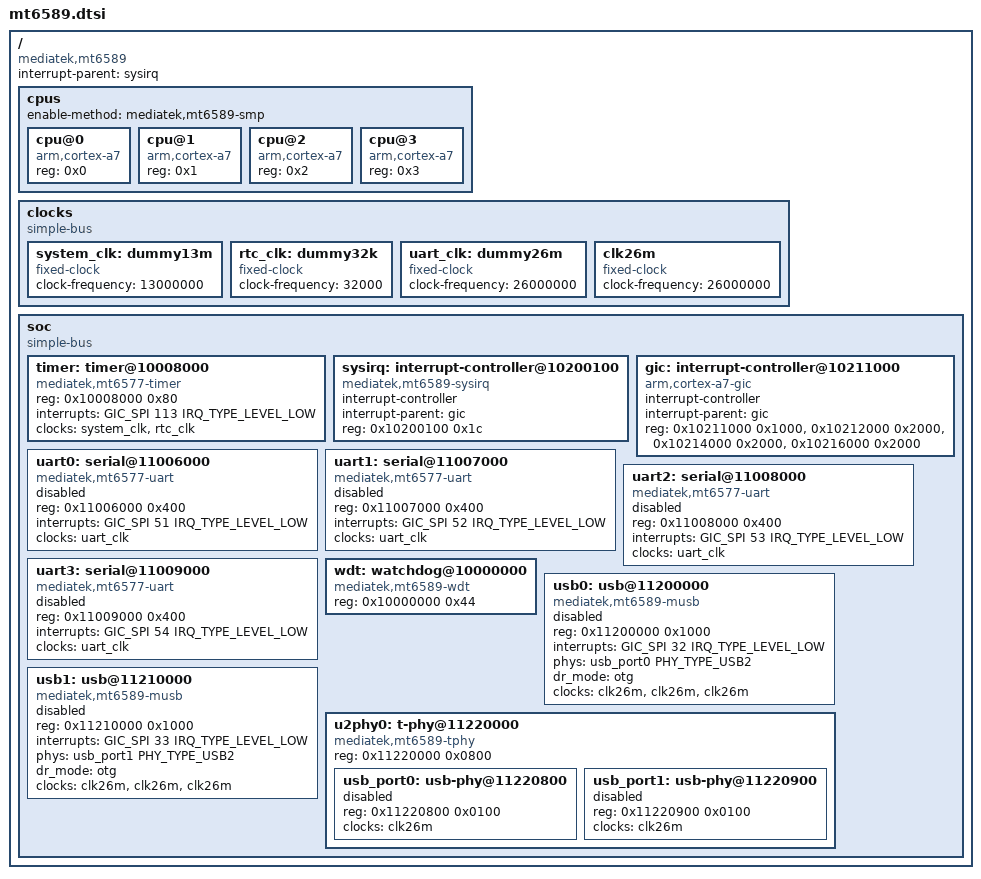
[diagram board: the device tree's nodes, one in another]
// SPDX-License-Identifier: GPL-2.0+
/*
 * Copyright (c) 2014 MundoReader S.L.
 * Author: Matthias Brugger <matthias.bgg@gmail.com>
 *
*/

#include <dt-bindings/interrupt-controller/irq.h>
#include <dt-bindings/interrupt-controller/arm-gic.h>
#include <dt-bindings/phy/phy.h>

/ {
	#address-cells = <1>;
	#size-cells = <1>;
	compatible = "mediatek,mt6589";
	interrupt-parent = <&sysirq>;

	cpus: cpus {
		#address-cells = <1>;
		#size-cells = <0>;
		enable-method = "mediatek,mt6589-smp";

		cpu@0 {
			device_type = "cpu";
			compatible = "arm,cortex-a7";
			reg = <0x0>;
		};
		cpu@1 {
			device_type = "cpu";
			compatible = "arm,cortex-a7";
			reg = <0x1>;
		};
		cpu@2 {
			device_type = "cpu";
			compatible = "arm,cortex-a7";
			reg = <0x2>;
		};
		cpu@3 {
			device_type = "cpu";
			compatible = "arm,cortex-a7";
			reg = <0x3>;
		};

	};

	clocks {
		#address-cells = <1>;
		#size-cells = <1>;
		compatible = "simple-bus";
		ranges;

		system_clk: dummy13m {
			compatible = "fixed-clock";
			clock-frequency = <13000000>;
			#clock-cells = <0>;
		};

		rtc_clk: dummy32k {
			compatible = "fixed-clock";
			clock-frequency = <32000>;
			#clock-cells = <0>;
		};

		uart_clk: dummy26m {
			compatible = "fixed-clock";
			clock-frequency = <26000000>;
			#clock-cells = <0>;
		};

		clk26m: clk26m {
			compatible = "fixed-clock";
			clock-frequency = <26000000>;
			#clock-cells = <0>;
		};
	};

	soc {
		#address-cells = <1>;
		#size-cells = <1>;
		compatible = "simple-bus";
		ranges;

		timer: timer@10008000 {
			compatible = "mediatek,mt6577-timer";
			reg = <0x10008000 0x80>;
			interrupts = <GIC_SPI 113 IRQ_TYPE_LEVEL_LOW>;
			clocks = <&system_clk>, <&rtc_clk>;
			clock-names = "system-clk", "rtc-clk";
		};

		sysirq: interrupt-controller@10200100 {
			compatible = "mediatek,mt6589-sysirq",
				     "mediatek,mt6577-sysirq";
			interrupt-controller;
			#interrupt-cells = <3>;
			interrupt-parent = <&gic>;
			reg = <0x10200100 0x1c>;
		};

		gic: interrupt-controller@10211000 {
			compatible = "arm,cortex-a7-gic";
			interrupt-controller;
			#interrupt-cells = <3>;
			interrupt-parent = <&gic>;
			reg = <0x10211000 0x1000>,
			      <0x10212000 0x2000>,
			      <0x10214000 0x2000>,
			      <0x10216000 0x2000>;
		};

		uart0: serial@11006000 {
			compatible = "mediatek,mt6577-uart";
			reg = <0x11006000 0x400>;
			interrupts = <GIC_SPI 51 IRQ_TYPE_LEVEL_LOW>;
			clocks = <&uart_clk>;
			status = "disabled";
		};

		uart1: serial@11007000 {
			compatible = "mediatek,mt6577-uart";
			reg = <0x11007000 0x400>;
			interrupts = <GIC_SPI 52 IRQ_TYPE_LEVEL_LOW>;
			clocks = <&uart_clk>;
			status = "disabled";
		};

		uart2: serial@11008000 {
			compatible = "mediatek,mt6577-uart";
			reg = <0x11008000 0x400>;
			interrupts = <GIC_SPI 53 IRQ_TYPE_LEVEL_LOW>;
			clocks = <&uart_clk>;
			status = "disabled";
		};

		uart3: serial@11009000 {
			compatible = "mediatek,mt6577-uart";
			reg = <0x11009000 0x400>;
			interrupts = <GIC_SPI 54 IRQ_TYPE_LEVEL_LOW>;
			clocks = <&uart_clk>;
			status = "disabled";
		};

		wdt: watchdog@10000000 {
			compatible = "mediatek,mt6589-wdt";
			reg = <0x10000000 0x44>;
		};

		/* USB 2.0 */
		usb0: usb@11200000 {
			compatible = "mediatek,mt6589-musb",
				     "mediatek,mtk-musb";
			reg = <0x11200000 0x1000>;
			interrupts = <GIC_SPI 32 IRQ_TYPE_LEVEL_LOW>;
			interrupt-names = "mc";
			phys = <&usb_port0 PHY_TYPE_USB2>;
			dr_mode = "otg";
			clocks = <&clk26m>, <&clk26m>, <&clk26m>;
			clock-names = "main", "mcu", "univpll";
			status = "disabled";
		};

		/* USB 1.1 */
		usb1: usb@11210000 {
			compatible = "mediatek,mt6589-musb",
				     "mediatek,mtk-musb";
			reg = <0x11210000 0x1000>;
			interrupts = <GIC_SPI 33 IRQ_TYPE_LEVEL_LOW>;
			interrupt-names = "mc";
			phys = <&usb_port1 PHY_TYPE_USB2>;
			dr_mode = "otg";
			clocks = <&clk26m>, <&clk26m>, <&clk26m>;
			clock-names = "main", "mcu", "univpll";
			status = "disabled";
		};

		u2phy0: t-phy@11220000 {
			compatible = "mediatek,mt6589-tphy",
				     "mediatek,generic-tphy-v1";
			reg = <0x11220000 0x0800>;
			ranges;
			status = "okay";
			#address-cells = <1>;
			#size-cells = <1>;

			usb_port0: usb-phy@11220800 {
				reg = <0x11220800 0x0100>;
				clocks = <&clk26m>;
				clock-names = "ref";
				#phy-cells = <1>;
				status = "disabled";
			};

			usb_port1: usb-phy@11220900 {
				reg = <0x11220900 0x0100>;
				clocks = <&clk26m>;
				clock-names = "ref";
				#phy-cells = <1>;
				status = "disabled";
			};
		};
	};
};
